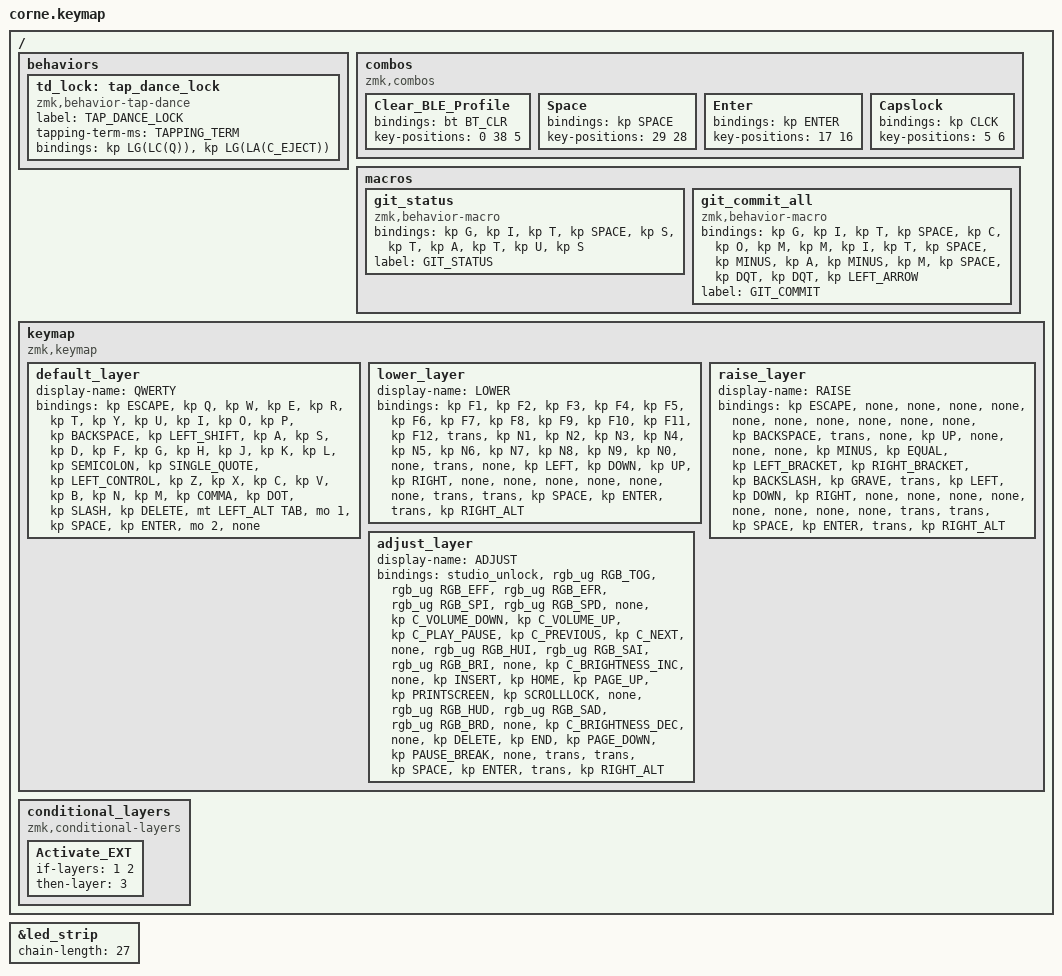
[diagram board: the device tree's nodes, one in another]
#include <behaviors.dtsi>
#include <dt-bindings/zmk/bt.h>
#include <dt-bindings/zmk/ext_power.h>
#include <dt-bindings/zmk/keys.h>
#include <dt-bindings/zmk/rgb.h>

&led_strip {
  chain-length = <27>;
  // chain-length = <27>;
  // 21 backlight + 6 glowlight
};


#define TAPPING_TERM 200

/ {
  behaviors {
    /*
    * td_lock groups locking functions into one key:
    *  - tap once to lock the host
    *  - tap twice to put the host to sleep
    */

    td_lock: tap_dance_lock {
      compatible = "zmk,behavior-tap-dance";
      label = "TAP_DANCE_LOCK";
      #binding-cells = <0>;
      tapping-term-ms = <TAPPING_TERM>;
      bindings = <&kp LG(LC(Q))>, <&kp LG(LA(C_EJECT))>;
    };
  };

  combos {
    compatible = "zmk,combos";

    Clear_BLE_Profile {
      bindings = <&bt BT_CLR>;
      key-positions = <0 38 5>;
    };

    Space {
      bindings = <&kp SPACE>;
      key-positions = <29 28>;
    };

    Enter {
      bindings = <&kp ENTER>;
      key-positions = <17 16>;
    };

    Capslock {
      bindings = <&kp CLCK>;
      key-positions = <5 6>;
    };
  };

  macros {
    git_status: git_status {
      compatible = "zmk,behavior-macro";
      #binding-cells = <0>;
      bindings = <&kp G &kp I &kp T &kp SPACE &kp S &kp T &kp A &kp T &kp U &kp S>;
      label = "GIT_STATUS";
    };
    git_commit_all: git_commit_all {
      compatible = "zmk,behavior-macro";
      #binding-cells = <0>;
      bindings = <&kp G &kp I &kp T &kp SPACE &kp C &kp O &kp M &kp M &kp I &kp T &kp SPACE &kp MINUS &kp A &kp MINUS &kp M &kp SPACE &kp DQT &kp DQT &kp LEFT_ARROW>;
      label = "GIT_COMMIT";
    };
  };

  keymap {
      compatible = "zmk,keymap";
        default_layer {
          display-name = "QWERTY";
          bindings = <
          &kp ESCAPE &kp Q &kp W &kp E &kp R &kp T &kp Y &kp U &kp I &kp O &kp P &kp BACKSPACE &kp LEFT_SHIFT &kp A &kp S &kp D &kp F &kp G &kp H &kp J &kp K &kp L &kp SEMICOLON &kp SINGLE_QUOTE &kp LEFT_CONTROL &kp Z &kp X &kp C &kp V &kp B &kp N &kp M &kp COMMA &kp DOT &kp SLASH &kp DELETE &mt LEFT_ALT TAB &mo 1 &kp SPACE &kp ENTER &mo 2 &none
          >;
        };
        lower_layer {
          display-name = "LOWER";
          bindings = <
          &kp F1 &kp F2 &kp F3 &kp F4 &kp F5 &kp F6 &kp F7 &kp F8 &kp F9 &kp F10 &kp F11 &kp F12 &trans &kp N1 &kp N2 &kp N3 &kp N4 &kp N5 &kp N6 &kp N7 &kp N8 &kp N9 &kp N0 &none &trans &none &kp LEFT &kp DOWN &kp UP &kp RIGHT &none &none &none &none &none &none &trans &trans &kp SPACE &kp ENTER &trans &kp RIGHT_ALT
          >;
        };
        raise_layer {
          display-name = "RAISE";
          bindings = <
          &kp ESCAPE &none &none &none &none &none &none &none &none &none &none &kp BACKSPACE &trans &none &kp UP &none &none &none &kp MINUS &kp EQUAL &kp LEFT_BRACKET &kp RIGHT_BRACKET &kp BACKSLASH &kp GRAVE &trans &kp LEFT &kp DOWN &kp RIGHT &none &none &none &none &none &none &none &none &trans &trans &kp SPACE &kp ENTER &trans &kp RIGHT_ALT
          >;
        };
        adjust_layer {
          display-name = "ADJUST";
          bindings = <
          &studio_unlock &rgb_ug RGB_TOG &rgb_ug RGB_EFF &rgb_ug RGB_EFR &rgb_ug RGB_SPI &rgb_ug RGB_SPD &none &kp C_VOLUME_DOWN &kp C_VOLUME_UP &kp C_PLAY_PAUSE &kp C_PREVIOUS &kp C_NEXT &none &rgb_ug RGB_HUI &rgb_ug RGB_SAI &rgb_ug RGB_BRI &none &kp C_BRIGHTNESS_INC &none &kp INSERT &kp HOME &kp PAGE_UP &kp PRINTSCREEN &kp SCROLLLOCK &none &rgb_ug RGB_HUD &rgb_ug RGB_SAD &rgb_ug RGB_BRD &none &kp C_BRIGHTNESS_DEC &none &kp DELETE &kp END &kp PAGE_DOWN &kp PAUSE_BREAK &none &trans &trans &kp SPACE &kp ENTER &trans &kp RIGHT_ALT
          >;
        };
    };
  

  conditional_layers {
    compatible = "zmk,conditional-layers";

    Activate_EXT {
      if-layers = <1 2>;
      then-layer = <3>;
    };
  };
};
